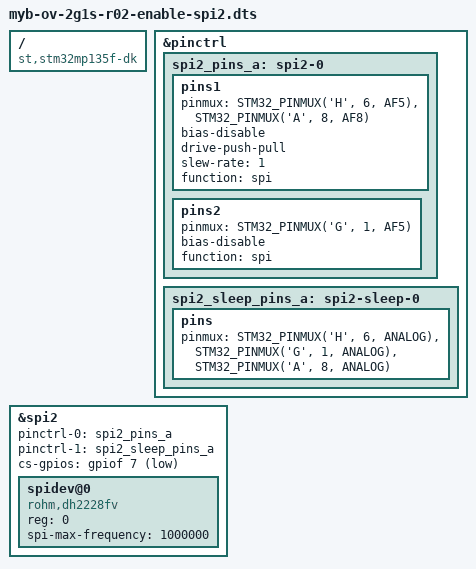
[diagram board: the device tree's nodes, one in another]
/dts-v1/;
/plugin/;

#include <dt-bindings/gpio/gpio.h>
#include <dt-bindings/pinctrl/stm32-pinfunc.h>

/ {
    compatible = "st,stm32mp135f-dk", "st,stm32mp135";

    fragment@0 {
        target = <&pinctrl>;
        __overlay__ {
            spi2_pins_a: spi2-0 {
                pins1 {
                    pinmux = <STM32_PINMUX('H', 6, AF5)>, /* SPI2_SCK (32) */
                            <STM32_PINMUX('A', 8, AF8)>; /* SPI2_MOSI (33) */
                    bias-disable;
                    drive-push-pull;
                    slew-rate = <1>;
                    function = "spi";
                };

                pins2 {
                    pinmux = <STM32_PINMUX('G', 1, AF5)>; /* SPI2_MISO (24) */
                    bias-disable;
                    function = "spi";
                };
            };

            spi2_sleep_pins_a: spi2-sleep-0 {
                pins {
                    pinmux = <STM32_PINMUX('H', 6, ANALOG)>, /* SPI2_SCK (32) */
                            <STM32_PINMUX('G', 1, ANALOG)>, /* SPI2_MISO (24) */
                            <STM32_PINMUX('A', 8, ANALOG)>; /* SPI2_MOSI (33) */
                };
            };
        };
    };

    fragment@1 {
        target = <&spi2>;
        __overlay__ {
            pinctrl-names = "default";
            pinctrl-0 = <&spi2_pins_a>;
            pinctrl-1 = <&spi2_sleep_pins_a>;
            status = "okay";
            cs-gpios = <&gpiof 7 GPIO_ACTIVE_LOW>;  /* Chip select GPIO */
            
            spidev@0 {
                compatible = "rohm,dh2228fv";
                reg = <0>;  /* Chip Select 0 */
                spi-max-frequency = <1000000>;
                status = "okay";
            };
        };
    };
};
